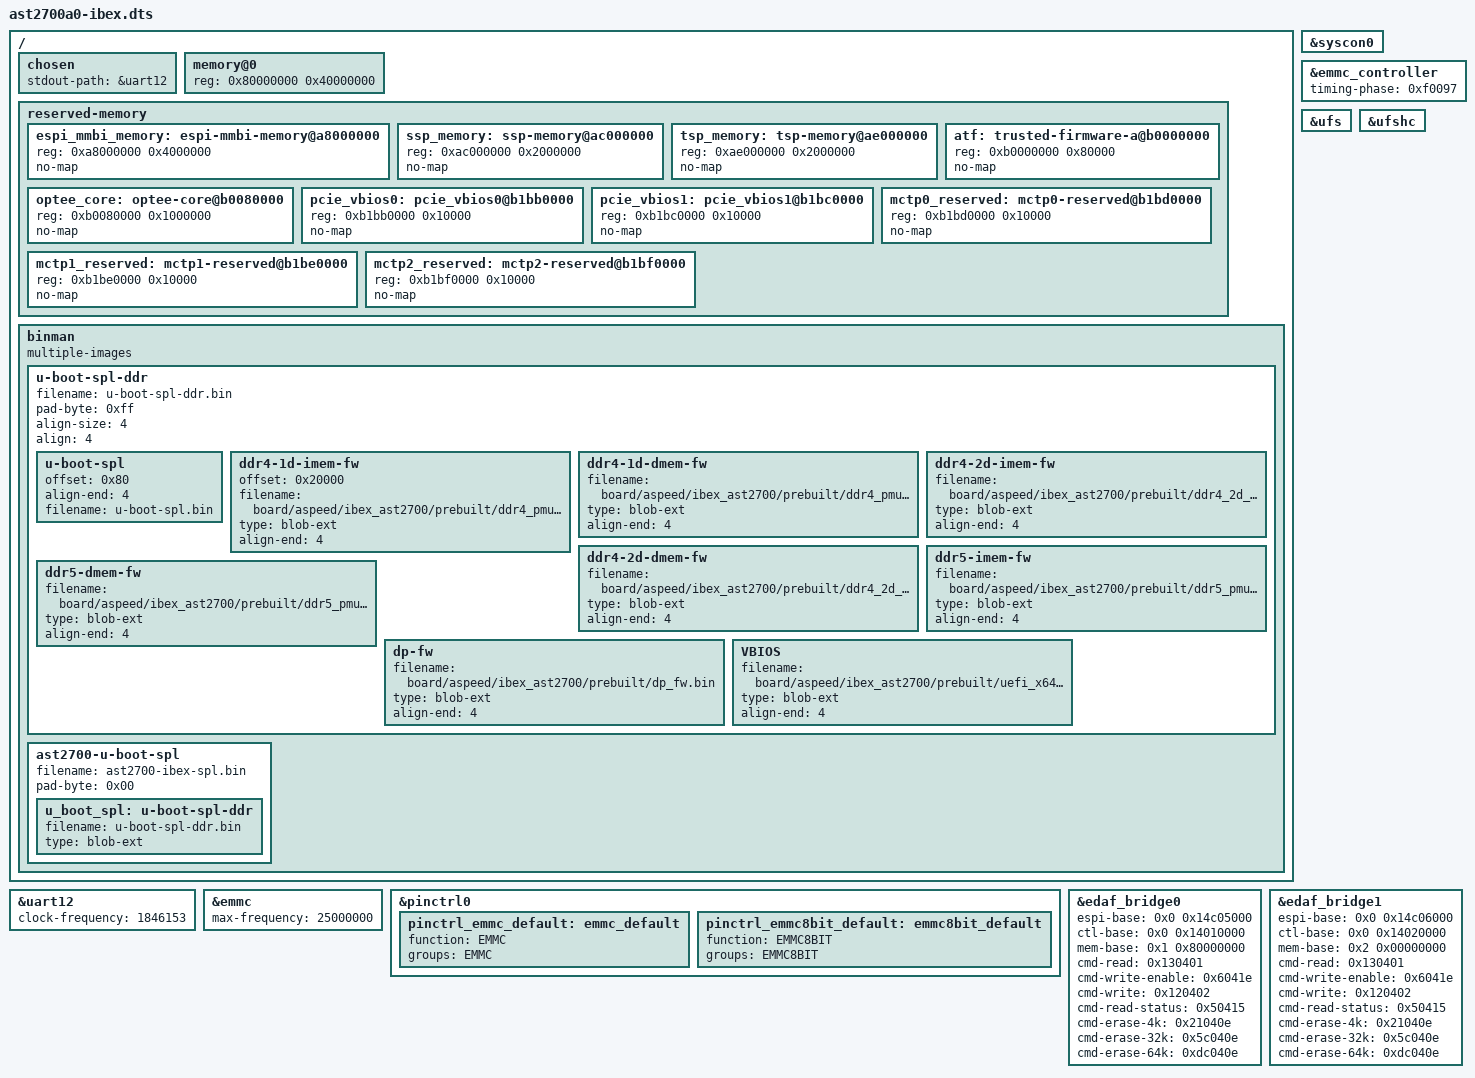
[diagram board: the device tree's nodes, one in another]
// SPDX-License-Identifier: (GPL-2.0 OR MIT)

/dts-v1/;

#include "ast2700.dtsi"

/ {
	chosen {
		stdout-path = &uart12;
	};

	memory@0 {
		device_type = "memory";
		reg = <0x80000000 0x40000000>;
	};

	reserved-memory {
		#address-cells = <1>;
		#size-cells = <1>;
		bootph-all;

		espi_mmbi_memory: espi-mmbi-memory@a8000000 {
			reg = <0xa8000000 0x4000000>;
			no-map;
		};

		ssp_memory: ssp-memory@ac000000 {
			reg = <0xac000000 0x2000000>;
			no-map;
		};

		tsp_memory: tsp-memory@ae000000 {
			reg = <0xae000000 0x2000000>;
			no-map;
		};

		atf: trusted-firmware-a@b0000000 {
			reg = <0xb0000000 0x80000>;
			no-map;
		};

		optee_core: optee-core@b0080000 {
			reg = <0xb0080000 0x1000000>;
			no-map;
		};

		pcie_vbios0: pcie_vbios0@b1bb0000 {
			reg = <0xb1bb0000 0x10000>;
			no-map;
			bootph-all;
		};

		pcie_vbios1: pcie_vbios1@b1bc0000 {
			reg = <0xb1bc0000 0x10000>;
			no-map;
			bootph-all;
		};

		mctp0_reserved: mctp0-reserved@b1bd0000 {
			reg = <0xb1bd0000 0x10000>;
			no-map;
		};

		mctp1_reserved: mctp1-reserved@b1be0000 {
			reg = <0xb1be0000 0x10000>;
			no-map;
		};

		mctp2_reserved: mctp2-reserved@b1bf0000 {
			reg = <0xb1bf0000 0x10000>;
			no-map;
		};
	};

	binman: binman {
		multiple-images;
	};
};

&uart12 {
	status = "okay";
	clock-frequency = <1846153>;
};

&syscon0 {
	status = "okay";
};

&emmc_controller {
	status = "okay";
	timing-phase = <0xf0097>;
};

&emmc {
	status = "okay";
	max-frequency = <25000000>;
};

&ufs {
	status = "okay";
};

&ufshc {
	status = "okay";
};

&pinctrl0 {
	pinctrl_emmc_default: emmc_default {
		function = "EMMC";
		groups = "EMMC";
	};

	pinctrl_emmc8bit_default: emmc8bit_default {
		function = "EMMC8BIT";
		groups = "EMMC8BIT";
	};
};

&edaf_bridge0 {
	status = "okay";
	espi-base = <0x0 0x14c05000>;
	ctl-base = <0x0 0x14010000>;
	mem-base = <0x1 0x80000000>;
	cmd-read = <0x130401>;
	cmd-write-enable = <0x6041e>;
	cmd-write = <0x120402>;
	cmd-read-status = <0x50415>;
	cmd-erase-4k = <0x21040e>;
	cmd-erase-32k = <0x5c040e>;
	cmd-erase-64k = <0xdc040e>;
};

&edaf_bridge1 {
	status = "okay";
	espi-base = <0x0 0x14c06000>;
	ctl-base = <0x0 0x14020000>;
	mem-base = <0x2 0x00000000>;
	cmd-read = <0x130401>;
	cmd-write-enable = <0x6041e>;
	cmd-write = <0x120402>;
	cmd-read-status = <0x50415>;
	cmd-erase-4k = <0x21040e>;
	cmd-erase-32k = <0x5c040e>;
	cmd-erase-64k = <0xdc040e>;
};

&binman {
	bootph-all;

	u-boot-spl-ddr {
		bootph-all;
		filename = "u-boot-spl-ddr.bin";
		pad-byte = <0xff>;
		align-size = <4>;
		align = <4>;

		u-boot-spl {
			offset = <0x80>;
			bootph-all;
			align-end = <4>;
			filename = "u-boot-spl.bin";
		};

		ddr4-1d-imem-fw {
			offset = <0x20000>;
			bootph-all;
			filename = "board/aspeed/ibex_ast2700/prebuilt/ddr4_pmu_train_imem.bin";
			type = "blob-ext";
			align-end = <4>;
		};
		ddr4-1d-dmem-fw {
			bootph-all;
			filename = "board/aspeed/ibex_ast2700/prebuilt/ddr4_pmu_train_dmem.bin";
			type = "blob-ext";
			align-end = <4>;
		};
		ddr4-2d-imem-fw {
			bootph-all;
			filename = "board/aspeed/ibex_ast2700/prebuilt/ddr4_2d_pmu_train_imem.bin";
			type = "blob-ext";
			align-end = <4>;
		};
		ddr4-2d-dmem-fw {
			bootph-all;
			filename = "board/aspeed/ibex_ast2700/prebuilt/ddr4_2d_pmu_train_dmem.bin";
			type = "blob-ext";
			align-end = <4>;
		};
		ddr5-imem-fw {
			bootph-all;
			filename = "board/aspeed/ibex_ast2700/prebuilt/ddr5_pmu_train_imem.bin";
			type = "blob-ext";
			align-end = <4>;
		};
		ddr5-dmem-fw {
			bootph-all;
			filename = "board/aspeed/ibex_ast2700/prebuilt/ddr5_pmu_train_dmem.bin";
			type = "blob-ext";
			align-end = <4>;
		};
		dp-fw {
			bootph-all;
			filename = "board/aspeed/ibex_ast2700/prebuilt/dp_fw.bin";
			type = "blob-ext";
			align-end = <4>;
		};
		VBIOS {
			bootph-all;
			filename = "board/aspeed/ibex_ast2700/prebuilt/uefi_x64_2700.bin";
			type = "blob-ext";
			align-end = <4>;
		};
	};

	ast2700-u-boot-spl {
		bootph-all;
		filename = "ast2700-ibex-spl.bin";
		pad-byte = <0x00>;

//		pre-load {
//			content = <&u_boot_spl>;
//			algo-name = "sha256,rsa2048";
//			key-name = "keys/dev.key";
//			header-size = <1024>;
//			version = <1>;
//		};

		u_boot_spl: u-boot-spl-ddr {
			bootph-all;
			filename = "u-boot-spl-ddr.bin";
			type = "blob-ext";
		};
	};
};
